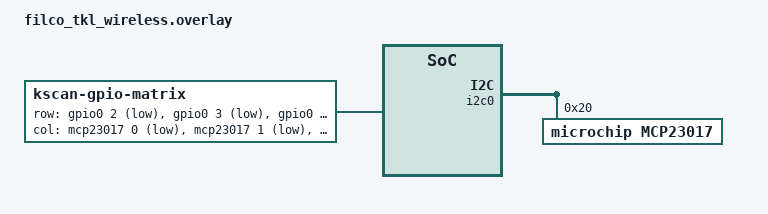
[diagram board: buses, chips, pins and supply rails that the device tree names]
/ {
    kscan: kscan {
        compatible = "zmk,kscan-gpio-matrix";

        diode-direction = "col2row";

        row-gpios = <
            &gpio0 2  (GPIO_ACTIVE_LOW)
            &gpio0 3  (GPIO_ACTIVE_LOW)
            &gpio0 4  (GPIO_ACTIVE_LOW)
            &gpio0 5  (GPIO_ACTIVE_LOW)
            &gpio0 6  (GPIO_ACTIVE_LOW)
            &gpio0 7  (GPIO_ACTIVE_LOW)
            &gpio0 8  (GPIO_ACTIVE_LOW)
        >;

        col-gpios = <
            &mcp23017 0  (GPIO_ACTIVE_LOW)
            &mcp23017 1  (GPIO_ACTIVE_LOW)
            &mcp23017 2  (GPIO_ACTIVE_LOW)
            &mcp23017 3  (GPIO_ACTIVE_LOW)
            &mcp23017 4  (GPIO_ACTIVE_LOW)
            &mcp23017 5  (GPIO_ACTIVE_LOW)
            &mcp23017 6  (GPIO_ACTIVE_LOW)
            &mcp23017 7  (GPIO_ACTIVE_LOW)
            &mcp23017 8  (GPIO_ACTIVE_LOW)
            &mcp23017 9  (GPIO_ACTIVE_LOW)
            &mcp23017 10 (GPIO_ACTIVE_LOW)
            &mcp23017 11 (GPIO_ACTIVE_LOW)
        >;

        # FIX deprecated warning
        debounce-press-ms = <5>;
        debounce-release-ms = <5>;
    };
};

&i2c0 {
    status = "okay";

    mcp23017: mcp23017@20 {
        compatible = "microchip,mcp23017";
        reg = <0x20>;
        gpio-controller;
        #gpio-cells = <2>;
    };
};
